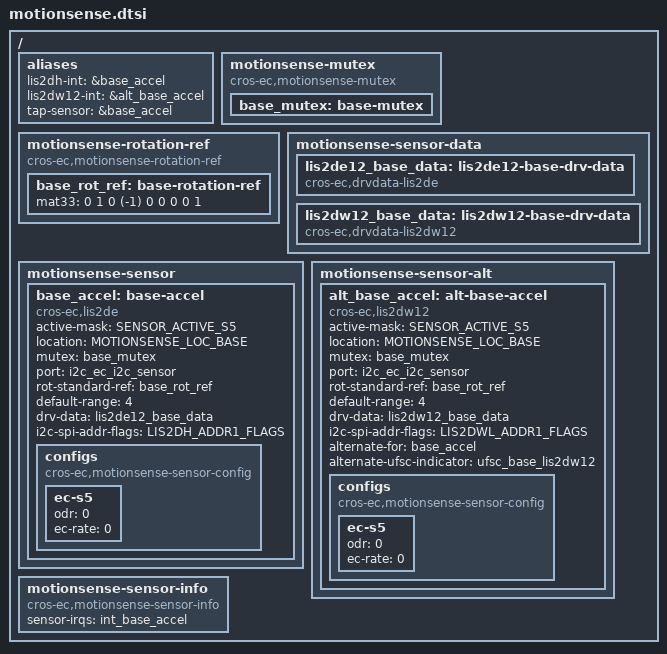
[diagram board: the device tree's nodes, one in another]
/* Copyright 2026 The ChromiumOS Authors
 * Use of this source code is governed by a BSD-style license that can be
 * found in the LICENSE file.
 */

#include <dt-bindings/motionsense/utils.h>

/ {
	aliases {
		/*
		 * Interrupt bindings for sensor devices.
		 */
		lis2dh-int = &base_accel;
		lis2dw12-int = &alt_base_accel;
		tap-sensor = &base_accel;
	};

	motionsense-mutex {
		compatible = "cros-ec,motionsense-mutex";
		base_mutex: base-mutex {
		};
	};

	/* Rotation matrix used by drivers. */
	motionsense-rotation-ref {
		compatible = "cros-ec,motionsense-rotation-ref";
		base_rot_ref: base-rotation-ref {
			mat33 = <0 1 0
				 (-1) 0 0
				 0 0 1>;
		};
	};

	motionsense-sensor-data {
		lis2de12_base_data: lis2de12-base-drv-data {
			compatible = "cros-ec,drvdata-lis2de";
			status = "okay";
		};
		lis2dw12_base_data: lis2dw12-base-drv-data {
			compatible = "cros-ec,drvdata-lis2dw12";
			status = "okay";
		};
	};

	motionsense-sensor {
		base_accel: base-accel {
			compatible = "cros-ec,lis2de";
			status = "okay";

			active-mask = "SENSOR_ACTIVE_S5";
			location = "MOTIONSENSE_LOC_BASE";
			mutex = <&base_mutex>;
			port = <&i2c_ec_i2c_sensor>;
			rot-standard-ref = <&base_rot_ref>;
			default-range = <4>;
			drv-data = <&lis2de12_base_data>;
			i2c-spi-addr-flags = "LIS2DH_ADDR1_FLAGS";
			configs {
				compatible =
					"cros-ec,motionsense-sensor-config";
				ec-s5 {
					odr = <0>;
					ec-rate = <0>;
				};
			};
		};
	};

	motionsense-sensor-alt {
		alt_base_accel: alt-base-accel {
			compatible = "cros-ec,lis2dw12";
			status = "okay";

			active-mask = "SENSOR_ACTIVE_S5";
			location = "MOTIONSENSE_LOC_BASE";
			mutex = <&base_mutex>;
			port = <&i2c_ec_i2c_sensor>;
			rot-standard-ref = <&base_rot_ref>;
			default-range = <4>;
			drv-data = <&lis2dw12_base_data>;
			i2c-spi-addr-flags = "LIS2DWL_ADDR1_FLAGS";
			alternate-for = <&base_accel>;
			alternate-ufsc-indicator = <&ufsc_base_lis2dw12>;
			configs {
				compatible =
					"cros-ec,motionsense-sensor-config";
				ec-s5 {
					odr = <0>;
					ec-rate = <0>;
				};
			};
		};
	};

	motionsense-sensor-info {
		compatible = "cros-ec,motionsense-sensor-info";

		/*
		 * List of GPIO interrupts that have to be enabled at initial
		 * stage.
		 */
		sensor-irqs = <&int_base_accel>;
	};
};
